# MDR1206AFI register map
Vendor: Milandr; File version: 2.0
CPU: BM-310S0, little endian
Registers are 32-bit, read-write, reset 0x0 unless marked. A register's access mark holds for its fields unless they carry their own. Offsets are from the block's base; lines under a group give offsets from that group; [hi:lo] are bit positions; {n}, {i} and the like mark numbered series; 'fields as' and 'values as' point back to an identical list; <NAME> marks a mode.

## Memory map
0x02000000 CLINT blocks up to offset 0xC000 — Core Local Interruptor
0x0D000000 CLIC size 0x8000 — Core Local Interrupt Controller
0x50000000 SSP1 size 0x1000 — SSP1 Interface
0x50008000 UART1 size 0x1000 — UART1 Controller
0x50010000 UART2 size 0x1000 — UART2 Controller
0x50018000 FLASH_CNTRL size 0x1000 — FLASH Memory Controller
0x50020000 RST_CLK size 0x1000 — RST_CLK description
0x50028000 DMA size 0x1000 — DMA Controller
0x50030000 I2C size 0x1000 — I2C Controller
0x50038000 UART3 size 0x1000 — UART3 Controller
0x50040000 ADC size 0x1000 — ADC Controller
0x50048000 WWDG size 0x1000
0x50050000 IWDG size 0x1000 — IWDG Controller
0x50058000 POWER size 0x1000 — Power Detector
0x50060000 BKP size 0x1000 — Backup domain
0x50068000 ADCUI size 0x1000 — ADCUI CONTROLLER
0x50070000 TIMER1 size 0x1000 — General purpose TIMER1
0x50078000 TIMER2 size 0x1000 — General purpose TIMER2
0x50080000 PORTA size 0x1000 — PORTA controller
0x50088000 PORTB size 0x1000 — PORTB Controller
0x50090000 PORTC size 0x1000 — PORTC Controller
0x50098000 CRC size 0x1000 — CRC Controller
0x500B8000 RANDOM size 0x1000 — Random Number Generator
0x500C0000 USART size 0x1000 — USART ISO 7816
0x500C8000 SSP2 size 0x1000 — SSP2 Interface
0x500D0000 SSP3 size 0x1000 — SSP3 Interface
0x500D8000 TIMER3 size 0x1000 — General purpose TIMER3
0x500E0000 TIMER4 size 0x1000 — General purpose TIMER4
0x500E8000 UART4 size 0x1000 — UART4 Controller
0x500F0000 PORTD size 0x1000 — PORTD Controller

## Interrupts
0 DMA_IRQ (DMA)
1 UART1_IRQ (UART1)
2 UART2_IRQ (UART2)
3 SSP1_IRQ (SSP1)
4 POWER_IRQ (POWER)
5 WWDG_IRQ (WWDG)
6 TIMER1_IRQ (TIMER1)
7 TIMER2_IRQ (TIMER2)
8 ADC_IRQ (ADC)
9 I2C_IRQ (I2C)
10 BKP_IRQ (BKP)
11 EXT_INT1_IRQ (PORTA)
12 EXT_INT2_IRQ (PORTB)
13 EXT_INT3_IRQ (PORTC)
14 ADCUI_F03_IRQn (ADCUI)
15 ADCUI_F1_IRQn (ADCUI)
16 ADCUI_F2_IRQn (ADCUI)
21 RANDOM_IRQ (RANDOM)
22 USART_IRQ (USART)
23 UART3_IRQ (UART3)
24 SSP2_IRQ (SSP2)
25 SSP3_IRQ (SSP3)
26 TIMER3_IRQ (TIMER3)
27 TIMER4_IRQ (TIMER4)
28 UART4_IRQ (UART4)

## CLINT — Core Local Interruptor
Base 0x02000000
0x00 CTMSIP — Software Interrupt Request/Clear Register
  [0] msip — Waiting for software interrupt
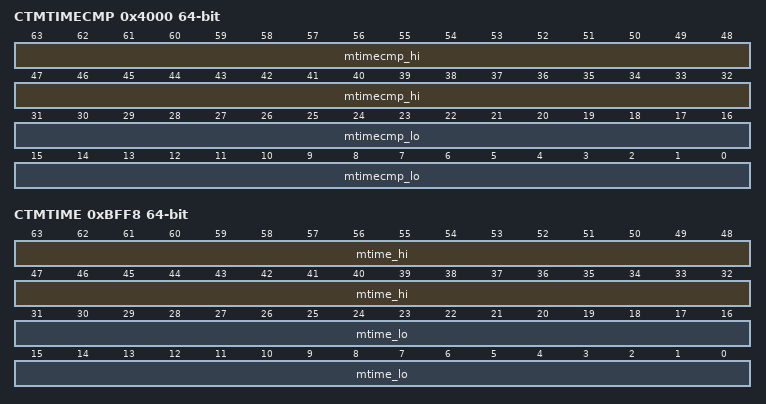
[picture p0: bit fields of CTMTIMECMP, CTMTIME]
0x4000 CTMTIMECMP 64-bit — Machine Timer Comparison Register
  [63:32] mtimecmp_hi — Higher part of the value of the comparison register
  [31:0] mtimecmp_lo — Lower part of the value of the comparison register
0xBFF8 CTMTIME 64-bit — Machine Timer Value Register
  [63:32] mtime_hi — Higher part of the timer value
  [31:0] mtime_lo — Lower part of the timer value

## SSP1 — SSP1 Interface
Base 0x50000000
Same registers: SSP2 0x500C8000, SSP3 0x500D0000
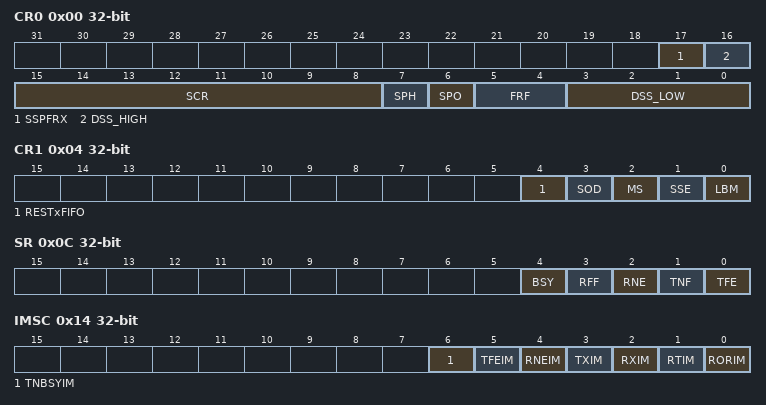
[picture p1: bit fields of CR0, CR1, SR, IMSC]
0x00 CR0 — Control Register 0
  [17] SSPFRX — SSPFRX description
  [16] DSS_HIGH — Data size select, high-order bit
  [15:8] SCR — Serial clock rate
  [7] SPH — SSPCLKOUT phase
  [6] SPO — SSPCLKOUT polarity
  [5:4] FRF — Frame format
  [3:0] DSS_LOW — Data size select, low-order bits
0x04 CR1 — Control Register 1
  [4] RESTxFIFO — Program reset of the TX FIFO
  [3] SOD — Slave-mode output disable
  [2] MS — Selects Master or Slave mode
  [1] SSE — Synchronous serial port enable
  [0] LBM — Loop back mode
0x08 DR — Data register
  [31:0] DATA — Data for transmission or receipt
0x0C SR ro — Status register
  [4] BSY — SSP busy flag
  [3] RFF — Receive FIFO full
  [2] RNE — Receive FIFO not empty
  [1] TNF — Transmit FIFO not full
  [0] TFE — Transmit FIFO empty
0x10 CPSR — Clock Prescaler Register
  [7:0] DVSR — Clock divisor. Must be an even number from 2 to 254
0x14 IMSC — Interrupt mask set or clear register
  [6] TNBSYIM — Transmitter shift register empty interrupt mask
  [5] TFEIM — Tramsmit FIFO empty interrupt mask
  [4] RNEIM — Receive FIFO empty interrupt mask
  [3] TXIM — Transmit FIFO interrupt mask
  [2] RXIM — Receive FIFO interrupt mask
  [1] RTIM — Receive timeout interrupt mask
  [0] RORIM — Receive overrun interrupt mask
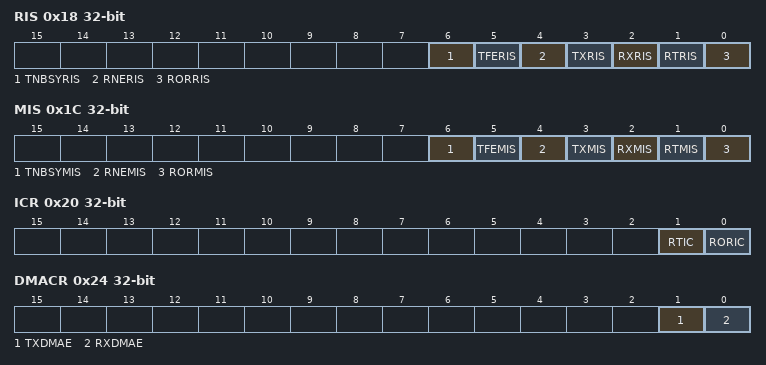
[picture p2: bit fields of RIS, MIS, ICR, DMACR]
0x18 RIS ro — Raw interrupt status register
  [6] TNBSYRIS — The raw interrupt state (prior to masking) of the SSPTNBSYINTR interrupt
  [5] TFERIS — The raw interrupt state (prior to masking) of the SSPTFEINTR interrupt
  [4] RNERIS — The raw interrupt state (prior to masking) of the SSPRNEINTR interrupt
  [3] TXRIS — The raw interrupt state (prior to masking) of the SSPTXINTR interrupt
  [2] RXRIS — The raw interrupt state (prior to masking) of the SSPRXINTR interrupt
  [1] RTRIS — The raw interrupt state (prior to masking) of the SSPRTINTR interrupt
  [0] RORRIS — The raw interrupt state (prior to masking) of the SSPRORINTR interrupt
0x1C MIS ro — Masked interrupt status register
  [6] TNBSYMIS — Masked interrupt status of the SSPTNBSYINTR
  [5] TFEMIS — Masked interrupt status of the SSPTFEINTR
  [4] RNEMIS — Masked interrupt status of the SSPRNEINTR
  [3] TXMIS — Masked interrupt status of the SSPTXINTR
  [2] RXMIS — Masked interrupt status of the SSPRXINTR
  [1] RTMIS — Masked interrupt status of the SSPRTINTR
  [0] RORMIS — Masked interrupt status of the SSPRORINTR
0x20 ICR wo — Interrupt clear register
  [1] RTIC — Clears the SSPRTINTR interrupt
  [0] RORIC — Clears the SSPRORINTR interrupt
0x24 DMACR — DMACR description
  [1] TXDMAE — If TXDMAE=1, DMA for the transmit FIFO is enabled
  [0] RXDMAE — If RXDMAE=1, DMA for the transmit FIFO is enabled
